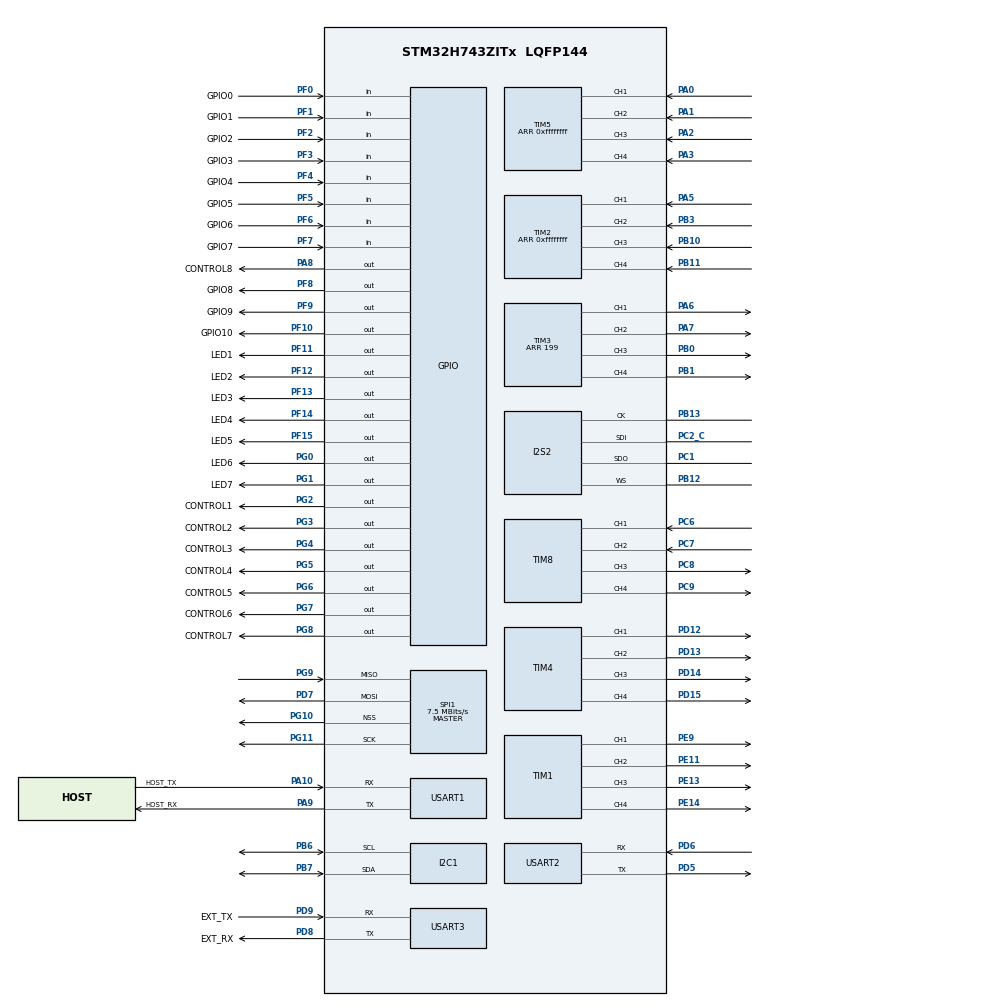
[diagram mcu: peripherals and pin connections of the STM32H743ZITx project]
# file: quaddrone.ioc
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Dma.Request0=TIM3_UP
Dma.Request1=TIM2_CH1
Dma.Request2=TIM2_CH2
Dma.Request3=TIM2_CH3
Dma.Request4=TIM2_CH4
Dma.Request5=TIM5_CH1
Dma.Request6=TIM5_CH2
Dma.Request7=TIM5_CH3
Dma.Request8=TIM5_CH4
Dma.TIM2_CH1.1.Direction=DMA_PERIPH_TO_MEMORY
Dma.TIM2_CH1.1.EventEnable=DISABLE
Dma.TIM2_CH1.1.FIFOMode=DMA_FIFOMODE_DISABLE
Dma.TIM2_CH1.1.Instance=DMA1_Stream1
Dma.TIM2_CH1.1.MemDataAlignment=DMA_MDATAALIGN_WORD
Dma.TIM2_CH1.1.MemInc=DMA_MINC_ENABLE
Dma.TIM2_CH1.1.Mode=DMA_NORMAL
Dma.TIM2_CH1.1.PeriphDataAlignment=DMA_PDATAALIGN_WORD
Dma.TIM2_CH1.1.PeriphInc=DMA_PINC_DISABLE
Dma.TIM2_CH1.1.Polarity=HAL_DMAMUX_REQ_GEN_RISING
Dma.TIM2_CH1.1.Priority=DMA_PRIORITY_LOW
Dma.TIM2_CH1.1.RequestNumber=1
Dma.TIM2_CH1.1.SignalID=NONE
Dma.TIM2_CH1.1.SyncEnable=DISABLE
Dma.TIM2_CH1.1.SyncPolarity=HAL_DMAMUX_SYNC_NO_EVENT
Dma.TIM2_CH1.1.SyncRequestNumber=1
Dma.TIM2_CH1.1.SyncSignalID=NONE
Dma.TIM2_CH2.2.Direction=DMA_PERIPH_TO_MEMORY
Dma.TIM2_CH2.2.EventEnable=DISABLE
Dma.TIM2_CH2.2.FIFOMode=DMA_FIFOMODE_DISABLE
Dma.TIM2_CH2.2.Instance=DMA1_Stream2
Dma.TIM2_CH2.2.MemDataAlignment=DMA_MDATAALIGN_WORD
Dma.TIM2_CH2.2.MemInc=DMA_MINC_ENABLE
Dma.TIM2_CH2.2.Mode=DMA_NORMAL
Dma.TIM2_CH2.2.PeriphDataAlignment=DMA_PDATAALIGN_WORD
Dma.TIM2_CH2.2.PeriphInc=DMA_PINC_DISABLE
Dma.TIM2_CH2.2.Polarity=HAL_DMAMUX_REQ_GEN_RISING
Dma.TIM2_CH2.2.Priority=DMA_PRIORITY_LOW
Dma.TIM2_CH2.2.RequestNumber=1
Dma.TIM2_CH2.2.SignalID=NONE
Dma.TIM2_CH2.2.SyncEnable=DISABLE
Dma.TIM2_CH2.2.SyncPolarity=HAL_DMAMUX_SYNC_NO_EVENT
Dma.TIM2_CH2.2.SyncRequestNumber=1
Dma.TIM2_CH2.2.SyncSignalID=NONE
Dma.TIM2_CH3.3.Direction=DMA_PERIPH_TO_MEMORY
Dma.TIM2_CH3.3.EventEnable=DISABLE
Dma.TIM2_CH3.3.FIFOMode=DMA_FIFOMODE_DISABLE
Dma.TIM2_CH3.3.Instance=DMA1_Stream3
Dma.TIM2_CH3.3.MemDataAlignment=DMA_MDATAALIGN_WORD
Dma.TIM2_CH3.3.MemInc=DMA_MINC_ENABLE
Dma.TIM2_CH3.3.Mode=DMA_NORMAL
Dma.TIM2_CH3.3.PeriphDataAlignment=DMA_PDATAALIGN_WORD
Dma.TIM2_CH3.3.PeriphInc=DMA_PINC_DISABLE
Dma.TIM2_CH3.3.Polarity=HAL_DMAMUX_REQ_GEN_RISING
Dma.TIM2_CH3.3.Priority=DMA_PRIORITY_LOW
Dma.TIM2_CH3.3.RequestNumber=1
Dma.TIM2_CH3.3.SignalID=NONE
Dma.TIM2_CH3.3.SyncEnable=DISABLE
Dma.TIM2_CH3.3.SyncPolarity=HAL_DMAMUX_SYNC_NO_EVENT
Dma.TIM2_CH3.3.SyncRequestNumber=1
Dma.TIM2_CH3.3.SyncSignalID=NONE
Dma.TIM2_CH4.4.Direction=DMA_PERIPH_TO_MEMORY
Dma.TIM2_CH4.4.EventEnable=DISABLE
Dma.TIM2_CH4.4.FIFOMode=DMA_FIFOMODE_DISABLE
Dma.TIM2_CH4.4.Instance=DMA1_Stream4
Dma.TIM2_CH4.4.MemDataAlignment=DMA_MDATAALIGN_WORD
Dma.TIM2_CH4.4.MemInc=DMA_MINC_ENABLE
Dma.TIM2_CH4.4.Mode=DMA_NORMAL
Dma.TIM2_CH4.4.PeriphDataAlignment=DMA_PDATAALIGN_WORD
Dma.TIM2_CH4.4.PeriphInc=DMA_PINC_DISABLE
Dma.TIM2_CH4.4.Polarity=HAL_DMAMUX_REQ_GEN_RISING
Dma.TIM2_CH4.4.Priority=DMA_PRIORITY_LOW
Dma.TIM2_CH4.4.RequestNumber=1
Dma.TIM2_CH4.4.SignalID=NONE
Dma.TIM2_CH4.4.SyncEnable=DISABLE
Dma.TIM2_CH4.4.SyncPolarity=HAL_DMAMUX_SYNC_NO_EVENT
Dma.TIM2_CH4.4.SyncRequestNumber=1
Dma.TIM2_CH4.4.SyncSignalID=NONE
Dma.TIM3_UP.0.Direction=DMA_MEMORY_TO_PERIPH
Dma.TIM3_UP.0.EventEnable=DISABLE
Dma.TIM3_UP.0.FIFOMode=DMA_FIFOMODE_DISABLE
Dma.TIM3_UP.0.Instance=DMA1_Stream0
Dma.TIM3_UP.0.MemDataAlignment=DMA_MDATAALIGN_WORD
Dma.TIM3_UP.0.MemInc=DMA_MINC_ENABLE
Dma.TIM3_UP.0.Mode=DMA_NORMAL
Dma.TIM3_UP.0.PeriphDataAlignment=DMA_PDATAALIGN_WORD
Dma.TIM3_UP.0.PeriphInc=DMA_PINC_DISABLE
Dma.TIM3_UP.0.Polarity=HAL_DMAMUX_REQ_GEN_RISING
Dma.TIM3_UP.0.Priority=DMA_PRIORITY_LOW
Dma.TIM3_UP.0.RequestNumber=1
Dma.TIM3_UP.0.SignalID=NONE
Dma.TIM3_UP.0.SyncEnable=DISABLE
Dma.TIM3_UP.0.SyncPolarity=HAL_DMAMUX_SYNC_NO_EVENT
Dma.TIM3_UP.0.SyncRequestNumber=1
Dma.TIM3_UP.0.SyncSignalID=NONE
Dma.TIM5_CH1.5.Direction=DMA_PERIPH_TO_MEMORY
Dma.TIM5_CH1.5.EventEnable=DISABLE
Dma.TIM5_CH1.5.FIFOMode=DMA_FIFOMODE_DISABLE
Dma.TIM5_CH1.5.Instance=DMA1_Stream5
Dma.TIM5_CH1.5.MemDataAlignment=DMA_MDATAALIGN_WORD
Dma.TIM5_CH1.5.MemInc=DMA_MINC_ENABLE
Dma.TIM5_CH1.5.Mode=DMA_NORMAL
Dma.TIM5_CH1.5.PeriphDataAlignment=DMA_PDATAALIGN_WORD
Dma.TIM5_CH1.5.PeriphInc=DMA_PINC_DISABLE
Dma.TIM5_CH1.5.Polarity=HAL_DMAMUX_REQ_GEN_RISING
Dma.TIM5_CH1.5.Priority=DMA_PRIORITY_LOW
Dma.TIM5_CH1.5.RequestNumber=1
Dma.TIM5_CH1.5.SignalID=NONE
Dma.TIM5_CH1.5.SyncEnable=DISABLE
Dma.TIM5_CH1.5.SyncPolarity=HAL_DMAMUX_SYNC_NO_EVENT
Dma.TIM5_CH1.5.SyncRequestNumber=1
Dma.TIM5_CH1.5.SyncSignalID=NONE
Dma.TIM5_CH2.6.Direction=DMA_PERIPH_TO_MEMORY
Dma.TIM5_CH2.6.EventEnable=DISABLE
Dma.TIM5_CH2.6.FIFOMode=DMA_FIFOMODE_DISABLE
Dma.TIM5_CH2.6.Instance=DMA1_Stream6
Dma.TIM5_CH2.6.MemDataAlignment=DMA_MDATAALIGN_WORD
Dma.TIM5_CH2.6.MemInc=DMA_MINC_ENABLE
Dma.TIM5_CH2.6.Mode=DMA_NORMAL
Dma.TIM5_CH2.6.PeriphDataAlignment=DMA_PDATAALIGN_WORD
Dma.TIM5_CH2.6.PeriphInc=DMA_PINC_DISABLE
Dma.TIM5_CH2.6.Polarity=HAL_DMAMUX_REQ_GEN_RISING
Dma.TIM5_CH2.6.Priority=DMA_PRIORITY_LOW
Dma.TIM5_CH2.6.RequestNumber=1
Dma.TIM5_CH2.6.SignalID=NONE
Dma.TIM5_CH2.6.SyncEnable=DISABLE
Dma.TIM5_CH2.6.SyncPolarity=HAL_DMAMUX_SYNC_NO_EVENT
Dma.TIM5_CH2.6.SyncRequestNumber=1
Dma.TIM5_CH2.6.SyncSignalID=NONE
Dma.TIM5_CH3.7.Direction=DMA_PERIPH_TO_MEMORY
Dma.TIM5_CH3.7.EventEnable=DISABLE
Dma.TIM5_CH3.7.FIFOMode=DMA_FIFOMODE_DISABLE
Dma.TIM5_CH3.7.Instance=DMA1_Stream7
Dma.TIM5_CH3.7.MemDataAlignment=DMA_MDATAALIGN_WORD
Dma.TIM5_CH3.7.MemInc=DMA_MINC_ENABLE
Dma.TIM5_CH3.7.Mode=DMA_NORMAL
Dma.TIM5_CH3.7.PeriphDataAlignment=DMA_PDATAALIGN_WORD
Dma.TIM5_CH3.7.PeriphInc=DMA_PINC_DISABLE
Dma.TIM5_CH3.7.Polarity=HAL_DMAMUX_REQ_GEN_RISING
Dma.TIM5_CH3.7.Priority=DMA_PRIORITY_LOW
Dma.TIM5_CH3.7.RequestNumber=1
Dma.TIM5_CH3.7.SignalID=NONE
Dma.TIM5_CH3.7.SyncEnable=DISABLE
Dma.TIM5_CH3.7.SyncPolarity=HAL_DMAMUX_SYNC_NO_EVENT
Dma.TIM5_CH3.7.SyncRequestNumber=1
Dma.TIM5_CH3.7.SyncSignalID=NONE
Dma.TIM5_CH4.8.Direction=DMA_PERIPH_TO_MEMORY
Dma.TIM5_CH4.8.EventEnable=DISABLE
Dma.TIM5_CH4.8.FIFOMode=DMA_FIFOMODE_DISABLE
Dma.TIM5_CH4.8.Instance=DMA2_Stream0
Dma.TIM5_CH4.8.MemDataAlignment=DMA_MDATAALIGN_WORD
Dma.TIM5_CH4.8.MemInc=DMA_MINC_ENABLE
Dma.TIM5_CH4.8.Mode=DMA_NORMAL
Dma.TIM5_CH4.8.PeriphDataAlignment=DMA_PDATAALIGN_WORD
Dma.TIM5_CH4.8.PeriphInc=DMA_PINC_DISABLE
Dma.TIM5_CH4.8.Polarity=HAL_DMAMUX_REQ_GEN_RISING
Dma.TIM5_CH4.8.Priority=DMA_PRIORITY_LOW
Dma.TIM5_CH4.8.RequestNumber=1
Dma.TIM5_CH4.8.SignalID=NONE
Dma.TIM5_CH4.8.SyncEnable=DISABLE
Dma.TIM5_CH4.8.SyncPolarity=HAL_DMAMUX_SYNC_NO_EVENT
Dma.TIM5_CH4.8.SyncRequestNumber=1
Dma.TIM5_CH4.8.SyncSignalID=NONE
I2C1.Timing=0x307075B1
I2S2.AudioFreq=I2S_AUDIOFREQ_32K
I2S2.DataFormat=I2S_DATAFORMAT_16B_EXTENDED
I2S2.ErrorAudioFreq=0.15 %
I2S2.FullDuplexMode=I2S_MODE_MASTER_FD
I2S2.Instance=SPI$Index
I2S2.RealAudioFreq=32.051 KHz
I2S2.VirtualMode=I2S_MODE_MASTER
Mcu.Family=STM32H7
Mcu.Name=STM32H743ZITx
Mcu.Package=LQFP144
NVIC.DMA1_Stream0_IRQn=true\:0\:0\:false\:false\:true\:false\:true
NVIC.DMA1_Stream1_IRQn=true\:0\:0\:false\:false\:true\:false\:true
NVIC.DMA1_Stream2_IRQn=true\:0\:0\:false\:false\:true\:false\:true
NVIC.DMA1_Stream3_IRQn=true\:0\:0\:false\:false\:true\:false\:true
NVIC.DMA1_Stream4_IRQn=true\:0\:0\:false\:false\:true\:false\:true
NVIC.DMA1_Stream5_IRQn=true\:0\:0\:false\:false\:true\:false\:true
NVIC.DMA1_Stream6_IRQn=true\:0\:0\:false\:false\:true\:false\:true
NVIC.DMA1_Stream7_IRQn=true\:0\:0\:false\:false\:true\:false\:true
NVIC.DMA2_Stream0_IRQn=true\:0\:0\:false\:false\:true\:false\:true
NVIC.PriorityGroup=NVIC_PRIORITYGROUP_4
NVIC.TIM1_BRK_IRQn=true\:0\:0\:false\:false\:true\:true\:true
NVIC.TIM1_CC_IRQn=true\:0\:0\:false\:false\:true\:true\:true
NVIC.TIM1_TRG_COM_IRQn=true\:0\:0\:false\:false\:true\:true\:true
NVIC.TIM1_UP_IRQn=true\:0\:0\:false\:false\:true\:true\:true
NVIC.TIM2_IRQn=true\:0\:0\:false\:false\:true\:true\:true
NVIC.TIM3_IRQn=true\:0\:0\:false\:false\:true\:true\:true
NVIC.TIM5_IRQn=true\:0\:0\:false\:false\:true\:true\:true
NVIC.USART1_IRQn=true\:0\:0\:false\:false\:true\:true\:true
NVIC.USART2_IRQn=true\:0\:0\:false\:false\:true\:true\:true
NVIC.USART3_IRQn=true\:0\:0\:false\:false\:true\:true\:true
PA0.Signal=S_TIM5_CH1
PA1.Signal=S_TIM5_CH2
PA10.GPIO_Label=HOST_TX
PA10.Mode=Asynchronous
PA10.Signal=USART1_RX
PA2.Signal=S_TIM5_CH3
PA3.Signal=S_TIM5_CH4
PA5.Signal=S_TIM2_CH1
PA6.Signal=S_TIM3_CH1
PA7.Signal=S_TIM3_CH2
PA8.GPIO_Label=CONTROL8
PA8.Signal=GPIO_Output
PA9.GPIO_Label=HOST_RX
PA9.Mode=Asynchronous
PA9.Signal=USART1_TX
PB0.Signal=S_TIM3_CH3
PB1.Signal=S_TIM3_CH4
PB10.Signal=S_TIM2_CH3
PB11.Signal=S_TIM2_CH4
PB12.Mode=Full_Duplex_Master
PB12.Signal=I2S2_WS
PB13.Mode=Full_Duplex_Master
PB13.Signal=I2S2_CK
PB3\ (JTDO/TRACESWO).Signal=S_TIM2_CH2
PB6.Mode=I2C
PB6.Signal=I2C1_SCL
PB7.Mode=I2C
PB7.Signal=I2C1_SDA
PC1.Mode=Full_Duplex_Master
PC1.Signal=I2S2_SDO
PC2_C.Mode=Full_Duplex_Master
PC2_C.Signal=I2S2_SDI
PC6.Signal=S_TIM8_CH1
PC7.Signal=S_TIM8_CH2
PC8.Signal=S_TIM8_CH3
PC9.Signal=S_TIM8_CH4
PD12.Signal=S_TIM4_CH1
PD13.Signal=S_TIM4_CH2
PD14.Signal=S_TIM4_CH3
PD15.Signal=S_TIM4_CH4
PD5.Mode=Asynchronous
PD5.Signal=USART2_TX
PD6.Mode=Asynchronous
PD6.Signal=USART2_RX
PD7.Mode=Full_Duplex_Master
PD7.Signal=SPI1_MOSI
PD8.GPIO_Label=EXT_RX
PD8.Mode=Asynchronous
PD8.Signal=USART3_TX
PD9.GPIO_Label=EXT_TX
PD9.Mode=Asynchronous
PD9.Signal=USART3_RX
PE11.Signal=S_TIM1_CH2
PE13.Signal=S_TIM1_CH3
PE14.Signal=S_TIM1_CH4
PE9.Signal=S_TIM1_CH1
PF0.GPIO_Label=GPIO0
PF0.Signal=GPIO_Input
PF1.GPIO_Label=GPIO1
PF1.Signal=GPIO_Input
PF10.GPIO_Label=GPIO10
PF10.Signal=GPIO_Output
PF11.GPIO_Label=LED1
PF11.Signal=GPIO_Output
PF12.GPIO_Label=LED2
PF12.Signal=GPIO_Output
PF13.GPIO_Label=LED3
PF13.Signal=GPIO_Output
PF14.GPIO_Label=LED4
PF14.Signal=GPIO_Output
PF15.GPIO_Label=LED5
PF15.Signal=GPIO_Output
PF2.GPIO_Label=GPIO2
PF2.Signal=GPIO_Input
PF3.GPIO_Label=GPIO3
PF3.Signal=GPIO_Input
PF4.GPIO_Label=GPIO4
PF4.Signal=GPIO_Input
PF5.GPIO_Label=GPIO5
PF5.Signal=GPIO_Input
PF6.GPIO_Label=GPIO6
PF6.Signal=GPIO_Input
PF7.GPIO_Label=GPIO7
PF7.Signal=GPIO_Input
PF8.GPIO_Label=GPIO8
PF8.Signal=GPIO_Output
PF9.GPIO_Label=GPIO9
PF9.Signal=GPIO_Output
PG0.GPIO_Label=LED6
PG0.Signal=GPIO_Output
PG1.GPIO_Label=LED7
PG1.Signal=GPIO_Output
PG10.Mode=NSS_Signal_Hard_Output
PG10.Signal=SPI1_NSS
PG11.Mode=Full_Duplex_Master
PG11.Signal=SPI1_SCK
PG2.GPIO_Label=CONTROL1
PG2.Signal=GPIO_Output
PG3.GPIO_Label=CONTROL2
PG3.Signal=GPIO_Output
PG4.GPIO_Label=CONTROL3
PG4.Signal=GPIO_Output
PG5.GPIO_Label=CONTROL4
PG5.Signal=GPIO_Output
PG6.GPIO_Label=CONTROL5
PG6.Signal=GPIO_Output
PG7.GPIO_Label=CONTROL6
PG7.Signal=GPIO_Output
PG8.GPIO_Label=CONTROL7
PG8.Signal=GPIO_Output
PG9.Mode=Full_Duplex_Master
PG9.Signal=SPI1_MISO
PH0-OSC_IN\ (PH0).Mode=HSE-External-Oscillator
PH0-OSC_IN\ (PH0).Signal=RCC_OSC_IN
PH1-OSC_OUT\ (PH1).Mode=HSE-External-Oscillator
PH1-OSC_OUT\ (PH1).Signal=RCC_OSC_OUT
ProjectManager.HeapSize=0x200
ProjectManager.StackSize=0x400
ProjectManager.TargetToolchain=SW4STM32
RCC.ADCFreq_Value=288000000
RCC.APB1Freq_Value=120000000
RCC.APB2Freq_Value=120000000
RCC.APB3Freq_Value=120000000
RCC.APB4Freq_Value=120000000
RCC.CortexFreq_Value=480000000
RCC.D1PPRE=RCC_APB3_DIV2
RCC.D2PPRE1=RCC_APB1_DIV2
RCC.D2PPRE2=RCC_APB2_DIV2
RCC.D3PPRE=RCC_APB4_DIV2
RCC.DIVM1=2
RCC.DIVM2=2
RCC.DIVN1=120
RCC.DIVN2=72
RCC.HCLKFreq_Value=240000000
RCC.HPRE=RCC_HCLK_DIV2
RCC.HSE_VALUE=16000000
RCC.PLLSourceVirtual=RCC_PLLSOURCE_HSE
RCC.SYSCLKFreq_VALUE=480000000
RCC.SYSCLKSource=RCC_SYSCLKSOURCE_PLLCLK
RCC.USART234578CLockSelection=RCC_USART234578CLKSOURCE_PLL2
RCC.USBFreq_Value=480000000
SH.S_TIM1_CH1.0=TIM1_CH1,PWM Generation1 CH1
SH.S_TIM1_CH2.0=TIM1_CH2,PWM Generation2 CH2
SH.S_TIM1_CH3.0=TIM1_CH3,PWM Generation3 CH3
SH.S_TIM1_CH4.0=TIM1_CH4,PWM Generation4 CH4
SH.S_TIM2_CH1.0=TIM2_CH1,Input_Capture1_from_TI1
SH.S_TIM2_CH1.1=TIM2_CH1
SH.S_TIM2_CH2.0=TIM2_CH2,Input_Capture2_from_TI2
SH.S_TIM2_CH3.0=TIM2_CH3,Input_Capture3_from_TI3
SH.S_TIM2_CH3.1=TIM2_CH3
SH.S_TIM2_CH4.0=TIM2_CH4,Input_Capture4_from_TI4
SH.S_TIM3_CH1.0=TIM3_CH1,PWM Generation1 CH1
SH.S_TIM3_CH2.0=TIM3_CH2,PWM Generation2 CH2
SH.S_TIM3_CH3.0=TIM3_CH3,PWM Generation3 CH3
SH.S_TIM3_CH4.0=TIM3_CH4,PWM Generation4 CH4
SH.S_TIM4_CH1.0=TIM4_CH1,PWM Generation1 CH1
SH.S_TIM4_CH2.0=TIM4_CH2,PWM Generation2 CH2
SH.S_TIM4_CH3.0=TIM4_CH3,PWM Generation3 CH3
SH.S_TIM4_CH4.0=TIM4_CH4,PWM Generation4 CH4
SH.S_TIM5_CH1.0=TIM5_CH1,Input_Capture1_from_TI1
SH.S_TIM5_CH1.1=TIM5_CH1
SH.S_TIM5_CH2.0=TIM5_CH2,Input_Capture2_from_TI2
SH.S_TIM5_CH3.0=TIM5_CH3,Input_Capture3_from_TI3
SH.S_TIM5_CH3.1=TIM5_CH3
SH.S_TIM5_CH4.0=TIM5_CH4,Input_Capture4_from_TI4
SH.S_TIM8_CH1.0=TIM8_CH1,Input_Capture1_from_TI1
SH.S_TIM8_CH2.0=TIM8_CH2,Input_Capture2_from_TI2
SH.S_TIM8_CH3.0=TIM8_CH3,PWM Generation3 CH3
SH.S_TIM8_CH4.0=TIM8_CH4,PWM Generation4 CH4
SPI1.BaudRatePrescaler=SPI_BAUDRATEPRESCALER_64
SPI1.CalculateBaudRate=7.5 MBits/s
SPI1.Direction=SPI_DIRECTION_2LINES
SPI1.Mode=SPI_MODE_MASTER
SPI1.VirtualNSS=VM_NSSHARD
SPI1.VirtualType=VM_MASTER
TIM1.Channel-PWM\ Generation1\ CH1=TIM_CHANNEL_1
TIM1.Channel-PWM\ Generation2\ CH2=TIM_CHANNEL_2
TIM1.Channel-PWM\ Generation3\ CH3=TIM_CHANNEL_3
TIM1.Channel-PWM\ Generation4\ CH4=TIM_CHANNEL_4
TIM2.Channel-Input_Capture1_from_TI1=TIM_CHANNEL_1
TIM2.Channel-Input_Capture2_from_TI2=TIM_CHANNEL_2
TIM2.Channel-Input_Capture3_from_TI3=TIM_CHANNEL_3
TIM2.Channel-Input_Capture4_from_TI4=TIM_CHANNEL_4
TIM2.ICPolarity_CH1=TIM_INPUTCHANNELPOLARITY_BOTHEDGE
TIM2.ICPolarity_CH2=TIM_INPUTCHANNELPOLARITY_BOTHEDGE
TIM2.ICPolarity_CH3=TIM_INPUTCHANNELPOLARITY_BOTHEDGE
TIM2.ICPolarity_CH4=TIM_INPUTCHANNELPOLARITY_BOTHEDGE
TIM2.Period=0xffffffff
TIM2.TIM_MasterOutputTrigger=TIM_TRGO_OC1
TIM2.TIM_MasterSlaveMode=TIM_MASTERSLAVEMODE_ENABLE
TIM3.AutoReloadPreload=TIM_AUTORELOAD_PRELOAD_ENABLE
TIM3.Channel-PWM\ Generation1\ CH1=TIM_CHANNEL_1
TIM3.Channel-PWM\ Generation2\ CH2=TIM_CHANNEL_2
TIM3.Channel-PWM\ Generation3\ CH3=TIM_CHANNEL_3
TIM3.Channel-PWM\ Generation4\ CH4=TIM_CHANNEL_4
TIM3.Period=199
TIM4.Channel-PWM\ Generation1\ CH1=TIM_CHANNEL_1
TIM4.Channel-PWM\ Generation2\ CH2=TIM_CHANNEL_2
TIM4.Channel-PWM\ Generation3\ CH3=TIM_CHANNEL_3
TIM4.Channel-PWM\ Generation4\ CH4=TIM_CHANNEL_4
TIM5.Channel-Input_Capture1_from_TI1=TIM_CHANNEL_1
TIM5.Channel-Input_Capture2_from_TI2=TIM_CHANNEL_2
TIM5.Channel-Input_Capture3_from_TI3=TIM_CHANNEL_3
TIM5.Channel-Input_Capture4_from_TI4=TIM_CHANNEL_4
TIM5.ICPolarity_CH1=TIM_INPUTCHANNELPOLARITY_BOTHEDGE
TIM5.ICPolarity_CH2=TIM_INPUTCHANNELPOLARITY_BOTHEDGE
TIM5.ICPolarity_CH3=TIM_INPUTCHANNELPOLARITY_BOTHEDGE
TIM5.ICPolarity_CH4=TIM_INPUTCHANNELPOLARITY_BOTHEDGE
TIM5.Period=0xffffffff
TIM8.Channel-Input_Capture1_from_TI1=TIM_CHANNEL_1
TIM8.Channel-Input_Capture2_from_TI2=TIM_CHANNEL_2
TIM8.Channel-Output\ Compare6\ No\ Output=TIM_CHANNEL_6
TIM8.Channel-PWM\ Generation3\ CH3=TIM_CHANNEL_3
TIM8.Channel-PWM\ Generation4\ CH4=TIM_CHANNEL_4
TIM8.Channel-PWM\ Generation5\ No\ Output=TIM_CHANNEL_5
USART1.VirtualMode-Asynchronous=VM_ASYNC
USART2.VirtualMode-Asynchronous=VM_ASYNC
USART3.VirtualMode-Asynchronous=VM_ASYNC
VP_TIM1_VS_ClockSourceINT.Mode=Internal
VP_TIM1_VS_ClockSourceITR.Mode=TriggerSource_ITR1
VP_TIM1_VS_ControllerModeReset.Mode=Reset Mode
VP_TIM2_VS_ClockSourceINT.Mode=Internal
VP_TIM3_VS_ClockSourceINT.Mode=Internal
VP_TIM3_VS_ClockSourceITR.Mode=TriggerSource_ITR1
VP_TIM3_VS_ControllerModeReset.Mode=Reset Mode
VP_TIM4_VS_ClockSourceINT.Mode=Internal
VP_TIM5_VS_ClockSourceINT.Mode=Internal
VP_TIM8_VS_ClockSourceINT.Mode=Internal
VP_TIM8_VS_no_output5.Mode=PWM Generation5 No Output
VP_TIM8_VS_no_output6.Mode=Output Compare6 No Output
board=custom

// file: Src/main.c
/* USER CODE BEGIN Header */
/**
  ******************************************************************************
  * @file           : main.c
  * @brief          : Main program body
  ******************************************************************************
  * @attention
  *
  * <h2><center>&copy; Copyright (c) 2020 STMicroelectronics.
  * All rights reserved.</center></h2>
  *
  * This software component is licensed by ST under BSD 3-Clause license,
  * the "License"; You may not use this file except in compliance with the
  * License. You may obtain a copy of the License at:
  *                        opensource.org/licenses/BSD-3-Clause
  *
  ******************************************************************************
  */
/* USER CODE END Header */

#include "main.h"

I2C_HandleTypeDef hi2c1;

I2S_HandleTypeDef hi2s2;

SPI_HandleTypeDef hspi1;

TIM_HandleTypeDef htim1;
TIM_HandleTypeDef htim2;
TIM_HandleTypeDef htim3;
TIM_HandleTypeDef htim4;
TIM_HandleTypeDef htim5;
TIM_HandleTypeDef htim8;
DMA_HandleTypeDef hdma_tim2_ch1;
DMA_HandleTypeDef hdma_tim2_ch2;
DMA_HandleTypeDef hdma_tim2_ch3;
DMA_HandleTypeDef hdma_tim2_ch4;
DMA_HandleTypeDef hdma_tim3_up;
DMA_HandleTypeDef hdma_tim5_ch1;
DMA_HandleTypeDef hdma_tim5_ch2;
DMA_HandleTypeDef hdma_tim5_ch3;
DMA_HandleTypeDef hdma_tim5_ch4;

UART_HandleTypeDef huart1;
UART_HandleTypeDef huart2;
UART_HandleTypeDef huart3;

void SystemClock_Config(void);
static void MX_GPIO_Init(void);
static void MX_DMA_Init(void);
static void MX_I2C1_Init(void);
static void MX_SPI1_Init(void);
static void MX_TIM1_Init(void);
static void MX_TIM2_Init(void);
static void MX_TIM3_Init(void);
static void MX_TIM4_Init(void);
static void MX_TIM5_Init(void);
static void MX_TIM8_Init(void);
static void MX_USART1_UART_Init(void);
static void MX_USART3_UART_Init(void);
static void MX_I2S2_Init(void);
static void MX_USART2_UART_Init(void);
/* USER CODE BEGIN PFP */

/* four channels, 16 bits per packet */
#define DShotChannels (4)
#define DShotWordLength (16)
#define DShotPacketLength (DShotWordLength + 1)
uint32_t dshot_ccr_buffer[DShotPacketLength][DShotChannels] __attribute__ ((aligned(4), section(".dma_buffer")));
uint32_t dshot_incoming_buffer[DShotChannels][2 * DShotWordLength] __attribute__ ((aligned(4), section(".dma_buffer")));
static const uint32_t DShotPeriod = 199; /* 200 - 1 */
static const uint32_t DShotHi = 149; /* 75% of 200 - 1 */
static const uint32_t DShotLo = 74; /* 50% of 75% of 200 - 1 */

/* USER CODE END PFP */

/* USER CODE BEGIN 0 */

void init_dshot()
{
	for (int i = 0; i < DShotChannels; ++i) {
		for (int j = 0; j < DShotPacketLength; ++j) {
			dshot_ccr_buffer[j][i] = 0;
		}
	}

	for (int i = 0; i < DShotChannels; ++i) {
		for (int j = 0; j < DShotWordLength; ++j) {
			dshot_incoming_buffer[i][j] = 0;
		}
	}
}

void send_channel_dshot(unsigned int channel, uint16_t pwm, unsigned int send_flag)
{
	uint32_t *p = &dshot_ccr_buffer[0][channel];
	for (int i = 15; i >= 0; --i) {
		*p = ((pwm >> i) & 1) ? DShotHi : DShotLo;
		p += DShotChannels;
	}

	*p = 0;
	p += DShotChannels;

	if (send_flag) {
		DMA_HandleTypeDef *hdma = htim3.hdma[0];
		DMA_Stream_TypeDef *dma_stream = hdma->Instance;
		dma_stream->NDTR = DShotPacketLength * DShotChannels;
		dma_stream->CR |= (DMA_SxCR_TCIE);
		dma_stream->CR |= (DMA_SxCR_EN);

		TIM_TypeDef *tim = &htim3.Instance;
		tim->EGR = TIM_EGR_UG;
	}
}

void load_dshot(uint16_t pwm[4])
{
	for (int channel = 0; channel < DShotChannels; ++channel) {
		uint32_t *p = &dshot_ccr_buffer[0][channel];
		uint16_t pulse_duration = pwm[channel];
		for (int i = 15; i >= 0; --i) {
			*p = ((pulse_duration >> i) & 1) ? DShotHi : DShotLo;
			p += DShotChannels;
		}
		*p = 0;
	}
}

void fire_dshot(void)
{
	TIM_HandleTypeDef *htim = &htim3;
	TIM_TypeDef *tim = htim->Instance;
	DMA_HandleTypeDef *hdma = htim->hdma[0];
	DMA_Stream_TypeDef *dma_stream = hdma->Instance;

	dma_stream->CR &= ~(DMA_SxCR_EN);
	dma_stream->NDTR = DShotPacketLength * DShotChannels;
	dma_stream->CR |= (DMA_SxCR_TCIE);
	dma_stream->M0AR = dshot_ccr_buffer;
	dma_stream->PAR = &tim->DMAR;
	dma_stream->CR |= (DMA_SxCR_EN);

	// tim->EGR = TIM_EGR_UG;
}

void send_dshot(uint16_t pwm[4], unsigned int send_flag)
{
	load_dshot(pwm);
	if (send_flag) { fire_dshot(); }
}

void recv_dshot()
{
	TIM_HandleTypeDef *htim = &htim5;
	TIM_TypeDef *tim = htim->Instance;
	DMA_HandleTypeDef *hdma;
	DMA_Stream_TypeDef *dma_stream;
	const int TimChan1DmaIndex = 1;
	const int TimChan2DmaIndex = 2;
	const int TimChan3DmaIndex = 3;
	const int TimChan4DmaIndex = 4;

	const uint32_t xfer_size = 2 * DShotWordLength;

	hdma = htim->hdma[TimChan1DmaIndex];
	dma_stream = hdma->Instance;
	dma_stream->CR &= ~(DMA_SxCR_EN);
	dma_stream->NDTR = xfer_size;
	dma_stream->CR |= (DMA_SxCR_TCIE);
	dma_stream->M0AR = dshot_incoming_buffer[0];
	dma_stream->PAR = &tim->CCR1;
	dma_stream->CR |= (DMA_SxCR_EN);

	hdma = htim->hdma[TimChan2DmaIndex];
	dma_stream = hdma->Instance;
	dma_stream->CR &= ~(DMA_SxCR_EN);
	dma_stream->NDTR = xfer_size;
	dma_stream->CR |= (DMA_SxCR_TCIE);
	dma_stream->M0AR = dshot_incoming_buffer[1];
	dma_stream->PAR = &tim->CCR2;
	dma_stream->CR |= (DMA_SxCR_EN);

	hdma = htim->hdma[TimChan3DmaIndex];
	dma_stream = hdma->Instance;
	dma_stream->CR &= ~(DMA_SxCR_EN);
	dma_stream->NDTR = xfer_size;
	dma_stream->CR |= (DMA_SxCR_TCIE);
	dma_stream->M0AR = dshot_incoming_buffer[2];
	dma_stream->PAR = &tim->CCR3;
	dma_stream->CR |= (DMA_SxCR_EN);

	hdma = htim->hdma[TimChan4DmaIndex];
	dma_stream = hdma->Instance;
	dma_stream->CR &= ~(DMA_SxCR_EN);
	dma_stream->NDTR = xfer_size;
	dma_stream->CR |= (DMA_SxCR_TCIE);
	dma_stream->M0AR = dshot_incoming_buffer[3];
	dma_stream->PAR = &tim->CCR4;
	dma_stream->CR |= (DMA_SxCR_EN);

}

int analyze_shot(int channel, uint16_t *result)
{
	uint32_t acc1 = 0, acc2 = 0, acc0 = DShotWordLength - 1;
	uint16_t bit_length[16];
	uint32_t *p = dshot_incoming_buffer[channel];
	uint32_t delta;
	for (int i = 0; i < acc0; ++i) {
		uint32_t t0 = p[2*i];
		delta = p[2*i+1] - t0;
		bit_length[i] = delta;
		delta = p[2*i+2] - t0;
		acc1 += delta;
		acc2 += (delta * delta);
	}
	uint32_t mean = acc1 / acc0;
	uint32_t var2 = acc2 / acc0;
	uint32_t var2_max = 100 + mean * mean;
	uint32_t tolerance = mean / 20; /* 5% tolerance */
	uint32_t thresh1 = 3 * mean / 4 - tolerance;
	uint32_t thresh0 = thresh1 / 2 + tolerance;
	uint16_t dshot = 0;
	int errors = 0;
	if (var2 <= var2_max) { /* calculated mean is a good central value */
		for (int i = 0; i < DShotWordLength; ++i) {
			dshot = (dshot << 1);
			if (bit_length[i] > thresh1) {
				dshot = dshot | 1;
			} else if (bit_length[i] < thresh0) {
			} else {
				++errors;
			}
		}
	}
	*result = dshot;
	return errors;
}

/* USER CODE END 0 */

int main(void)
{

  /* MCU Configuration--------------------------------------------------------*/

  /* Reset of all peripherals, Initializes the Flash interface and the Systick. */
  HAL_Init();

  /* Configure the system clock */
  SystemClock_Config();

  /* Initialize all configured peripherals */
  MX_GPIO_Init();
  MX_DMA_Init();
  MX_I2C1_Init();
  MX_SPI1_Init();
  MX_TIM1_Init();
  MX_TIM2_Init();
  MX_TIM3_Init();
  MX_TIM4_Init();
  MX_TIM5_Init();
  MX_TIM8_Init();
  MX_USART1_UART_Init();
  MX_USART3_UART_Init();
  MX_I2S2_Init();
  MX_USART2_UART_Init();
  /* USER CODE BEGIN 2 */

  init_dshot();

  uint16_t pwm[4];
  pwm[0] = 0xaaaa;
  pwm[1] = 0x5555;
  pwm[2] = 0xcccc;
  pwm[3] = 0x3333;
  load_dshot(pwm);

  /* USER CODE END 2 */

  /* Infinite loop */
  /* USER CODE BEGIN WHILE */
  uint16_t dshot;
  int rc, channel = 0;
  while (1)
  {
	  recv_dshot();
	  fire_dshot();
	  HAL_Delay(100);
	  rc = analyze_shot(channel, &dshot);

    /* USER CODE END WHILE */

  }
}

void SystemClock_Config(void)
{
  RCC_OscInitTypeDef RCC_OscInitStruct = {0};
  RCC_ClkInitTypeDef RCC_ClkInitStruct = {0};
  RCC_PeriphCLKInitTypeDef PeriphClkInitStruct = {0};

  /** Supply configuration update enable
  */
  HAL_PWREx_ConfigSupply(PWR_LDO_SUPPLY);
  /** Configure the main internal regulator output voltage
  */
  __HAL_PWR_VOLTAGESCALING_CONFIG(PWR_REGULATOR_VOLTAGE_SCALE0);

  while(!__HAL_PWR_GET_FLAG(PWR_FLAG_VOSRDY)) {}
  /** Macro to configure the PLL clock source
  */
  __HAL_RCC_PLL_PLLSOURCE_CONFIG(RCC_PLLSOURCE_HSE);
  /** Initializes the CPU, AHB and APB busses clocks
  */
  RCC_OscInitStruct.OscillatorType = RCC_OSCILLATORTYPE_HSE;
  RCC_OscInitStruct.HSEState = RCC_HSE_ON;
  RCC_OscInitStruct.PLL.PLLState = RCC_PLL_ON;
  RCC_OscInitStruct.PLL.PLLSource = RCC_PLLSOURCE_HSE;
  RCC_OscInitStruct.PLL.PLLM = 2;
  RCC_OscInitStruct.PLL.PLLN = 120;
  RCC_OscInitStruct.PLL.PLLP = 2;
  RCC_OscInitStruct.PLL.PLLQ = 2;
  RCC_OscInitStruct.PLL.PLLR = 2;
  RCC_OscInitStruct.PLL.PLLRGE = RCC_PLL1VCIRANGE_3;
  RCC_OscInitStruct.PLL.PLLVCOSEL = RCC_PLL1VCOWIDE;
  RCC_OscInitStruct.PLL.PLLFRACN = 0;
  if (HAL_RCC_OscConfig(&RCC_OscInitStruct) != HAL_OK)
  {
    Error_Handler();
  }
  /** Initializes the CPU, AHB and APB busses clocks
  */
  RCC_ClkInitStruct.ClockType = RCC_CLOCKTYPE_HCLK|RCC_CLOCKTYPE_SYSCLK
                              |RCC_CLOCKTYPE_PCLK1|RCC_CLOCKTYPE_PCLK2
                              |RCC_CLOCKTYPE_D3PCLK1|RCC_CLOCKTYPE_D1PCLK1;
  RCC_ClkInitStruct.SYSCLKSource = RCC_SYSCLKSOURCE_PLLCLK;
  RCC_ClkInitStruct.SYSCLKDivider = RCC_SYSCLK_DIV1;
  RCC_ClkInitStruct.AHBCLKDivider = RCC_HCLK_DIV2;
  RCC_ClkInitStruct.APB3CLKDivider = RCC_APB3_DIV2;
  RCC_ClkInitStruct.APB1CLKDivider = RCC_APB1_DIV2;
  RCC_ClkInitStruct.APB2CLKDivider = RCC_APB2_DIV2;
  RCC_ClkInitStruct.APB4CLKDivider = RCC_APB4_DIV2;

  if (HAL_RCC_ClockConfig(&RCC_ClkInitStruct, FLASH_LATENCY_4) != HAL_OK)
  {
    Error_Handler();
  }
  PeriphClkInitStruct.PeriphClockSelection = RCC_PERIPHCLK_USART3|RCC_PERIPHCLK_USART2
                              |RCC_PERIPHCLK_USART1|RCC_PERIPHCLK_SPI1
                              |RCC_PERIPHCLK_SPI2|RCC_PERIPHCLK_I2C1;
  PeriphClkInitStruct.PLL2.PLL2M = 2;
  PeriphClkInitStruct.PLL2.PLL2N = 72;
  PeriphClkInitStruct.PLL2.PLL2P = 2;
  PeriphClkInitStruct.PLL2.PLL2Q = 2;
  PeriphClkInitStruct.PLL2.PLL2R = 2;
  PeriphClkInitStruct.PLL2.PLL2RGE = RCC_PLL2VCIRANGE_3;
  PeriphClkInitStruct.PLL2.PLL2VCOSEL = RCC_PLL2VCOWIDE;
  PeriphClkInitStruct.PLL2.PLL2FRACN = 0;
  PeriphClkInitStruct.Spi123ClockSelection = RCC_SPI123CLKSOURCE_PLL;
  PeriphClkInitStruct.Usart234578ClockSelection = RCC_USART234578CLKSOURCE_PLL2;
  PeriphClkInitStruct.Usart16ClockSelection = RCC_USART16CLKSOURCE_D2PCLK2;
  PeriphClkInitStruct.I2c123ClockSelection = RCC_I2C123CLKSOURCE_D2PCLK1;
  if (HAL_RCCEx_PeriphCLKConfig(&PeriphClkInitStruct) != HAL_OK)
  {
    Error_Handler();
  }
}

static void MX_I2C1_Init(void)
{

  hi2c1.Instance = I2C1;
  hi2c1.Init.Timing = 0x307075B1;
  hi2c1.Init.OwnAddress1 = 0;
  hi2c1.Init.AddressingMode = I2C_ADDRESSINGMODE_7BIT;
  hi2c1.Init.DualAddressMode = I2C_DUALADDRESS_DISABLE;
  hi2c1.Init.OwnAddress2 = 0;
  hi2c1.Init.OwnAddress2Masks = I2C_OA2_NOMASK;
  hi2c1.Init.GeneralCallMode = I2C_GENERALCALL_DISABLE;
  hi2c1.Init.NoStretchMode = I2C_NOSTRETCH_DISABLE;
  if (HAL_I2C_Init(&hi2c1) != HAL_OK)
  {
    Error_Handler();
  }
  /** Configure Analogue filter
  */
  if (HAL_I2CEx_ConfigAnalogFilter(&hi2c1, I2C_ANALOGFILTER_ENABLE) != HAL_OK)
  {
    Error_Handler();
  }
  /** Configure Digital filter
  */
  if (HAL_I2CEx_ConfigDigitalFilter(&hi2c1, 0) != HAL_OK)
  {
    Error_Handler();
  }

}

static void MX_I2S2_Init(void)
{

  hi2s2.Instance = SPI2;
  hi2s2.Init.Mode = I2S_MODE_MASTER_TX;
  hi2s2.Init.Standard = I2S_STANDARD_PHILIPS;
  hi2s2.Init.DataFormat = I2S_DATAFORMAT_16B_EXTENDED;
  hi2s2.Init.MCLKOutput = I2S_MCLKOUTPUT_DISABLE;
  hi2s2.Init.AudioFreq = I2S_AUDIOFREQ_32K;
  hi2s2.Init.CPOL = I2S_CPOL_LOW;
  hi2s2.Init.FirstBit = I2S_FIRSTBIT_MSB;
  hi2s2.Init.WSInversion = I2S_WS_INVERSION_DISABLE;
  hi2s2.Init.Data24BitAlignment = I2S_DATA_24BIT_ALIGNMENT_RIGHT;
  hi2s2.Init.MasterKeepIOState = I2S_MASTER_KEEP_IO_STATE_DISABLE;
  if (HAL_I2S_Init(&hi2s2) != HAL_OK)
  {
    Error_Handler();
  }

}

static void MX_SPI1_Init(void)
{

  /* SPI1 parameter configuration*/
  hspi1.Instance = SPI1;
  hspi1.Init.Mode = SPI_MODE_MASTER;
  hspi1.Init.Direction = SPI_DIRECTION_2LINES;
  hspi1.Init.DataSize = SPI_DATASIZE_4BIT;
  hspi1.Init.CLKPolarity = SPI_POLARITY_LOW;
  hspi1.Init.CLKPhase = SPI_PHASE_1EDGE;
  hspi1.Init.NSS = SPI_NSS_HARD_OUTPUT;
  hspi1.Init.BaudRatePrescaler = SPI_BAUDRATEPRESCALER_64;
  hspi1.Init.FirstBit = SPI_FIRSTBIT_MSB;
  hspi1.Init.TIMode = SPI_TIMODE_DISABLE;
  hspi1.Init.CRCCalculation = SPI_CRCCALCULATION_DISABLE;
  hspi1.Init.CRCPolynomial = 0x0;
  hspi1.Init.NSSPMode = SPI_NSS_PULSE_ENABLE;
  hspi1.Init.NSSPolarity = SPI_NSS_POLARITY_LOW;
  hspi1.Init.FifoThreshold = SPI_FIFO_THRESHOLD_01DATA;
  hspi1.Init.TxCRCInitializationPattern = SPI_CRC_INITIALIZATION_ALL_ZERO_PATTERN;
  hspi1.Init.RxCRCInitializationPattern = SPI_CRC_INITIALIZATION_ALL_ZERO_PATTERN;
  hspi1.Init.MasterSSIdleness = SPI_MASTER_SS_IDLENESS_00CYCLE;
  hspi1.Init.MasterInterDataIdleness = SPI_MASTER_INTERDATA_IDLENESS_00CYCLE;
  hspi1.Init.MasterReceiverAutoSusp = SPI_MASTER_RX_AUTOSUSP_DISABLE;
  hspi1.Init.MasterKeepIOState = SPI_MASTER_KEEP_IO_STATE_DISABLE;
  hspi1.Init.IOSwap = SPI_IO_SWAP_DISABLE;
  if (HAL_SPI_Init(&hspi1) != HAL_OK)
  {
    Error_Handler();
  }

}

static void MX_TIM1_Init(void)
{

  TIM_ClockConfigTypeDef sClockSourceConfig = {0};
  TIM_SlaveConfigTypeDef sSlaveConfig = {0};
  TIM_MasterConfigTypeDef sMasterConfig = {0};
  TIM_OC_InitTypeDef sConfigOC = {0};
  TIM_BreakDeadTimeConfigTypeDef sBreakDeadTimeConfig = {0};

  htim1.Instance = TIM1;
  htim1.Init.Prescaler = 0;
  htim1.Init.CounterMode = TIM_COUNTERMODE_UP;
  htim1.Init.Period = 0;
  htim1.Init.ClockDivision = TIM_CLOCKDIVISION_DIV1;
  htim1.Init.RepetitionCounter = 0;
  htim1.Init.AutoReloadPreload = TIM_AUTORELOAD_PRELOAD_DISABLE;
  if (HAL_TIM_Base_Init(&htim1) != HAL_OK)
  {
    Error_Handler();
  }
  sClockSourceConfig.ClockSource = TIM_CLOCKSOURCE_INTERNAL;
  if (HAL_TIM_ConfigClockSource(&htim1, &sClockSourceConfig) != HAL_OK)
  {
    Error_Handler();
  }
  if (HAL_TIM_PWM_Init(&htim1) != HAL_OK)
  {
    Error_Handler();
  }
  sSlaveConfig.SlaveMode = TIM_SLAVEMODE_RESET;
  sSlaveConfig.InputTrigger = TIM_TS_ITR1;
  if (HAL_TIM_SlaveConfigSynchro(&htim1, &sSlaveConfig) != HAL_OK)
  {
    Error_Handler();
  }
  sMasterConfig.MasterOutputTrigger = TIM_TRGO_RESET;
  sMasterConfig.MasterOutputTrigger2 = TIM_TRGO2_RESET;
  sMasterConfig.MasterSlaveMode = TIM_MASTERSLAVEMODE_DISABLE;
  if (HAL_TIMEx_MasterConfigSynchronization(&htim1, &sMasterConfig) != HAL_OK)
  {
    Error_Handler();
  }
  sConfigOC.OCMode = TIM_OCMODE_PWM1;
  sConfigOC.Pulse = 0;
  sConfigOC.OCPolarity = TIM_OCPOLARITY_HIGH;
  sConfigOC.OCNPolarity = TIM_OCNPOLARITY_HIGH;
  sConfigOC.OCFastMode = TIM_OCFAST_DISABLE;
  sConfigOC.OCIdleState = TIM_OCIDLESTATE_RESET;
  sConfigOC.OCNIdleState = TIM_OCNIDLESTATE_RESET;
  if (HAL_TIM_PWM_ConfigChannel(&htim1, &sConfigOC, TIM_CHANNEL_1) != HAL_OK)
  {
    Error_Handler();
  }
  if (HAL_TIM_PWM_ConfigChannel(&htim1, &sConfigOC, TIM_CHANNEL_2) != HAL_OK)
  {
    Error_Handler();
  }
  if (HAL_TIM_PWM_ConfigChannel(&htim1, &sConfigOC, TIM_CHANNEL_3) != HAL_OK)
  {
    Error_Handler();
  }
  if (HAL_TIM_PWM_ConfigChannel(&htim1, &sConfigOC, TIM_CHANNEL_4) != HAL_OK)
  {
    Error_Handler();
  }
  sBreakDeadTimeConfig.OffStateRunMode = TIM_OSSR_DISABLE;
  sBreakDeadTimeConfig.OffStateIDLEMode = TIM_OSSI_DISABLE;
  sBreakDeadTimeConfig.LockLevel = TIM_LOCKLEVEL_OFF;
  sBreakDeadTimeConfig.DeadTime = 0;
  sBreakDeadTimeConfig.BreakState = TIM_BREAK_DISABLE;
  sBreakDeadTimeConfig.BreakPolarity = TIM_BREAKPOLARITY_HIGH;
  sBreakDeadTimeConfig.BreakFilter = 0;
  sBreakDeadTimeConfig.Break2State = TIM_BREAK2_DISABLE;
  sBreakDeadTimeConfig.Break2Polarity = TIM_BREAK2POLARITY_HIGH;
  sBreakDeadTimeConfig.Break2Filter = 0;
  sBreakDeadTimeConfig.AutomaticOutput = TIM_AUTOMATICOUTPUT_DISABLE;
  if (HAL_TIMEx_ConfigBreakDeadTime(&htim1, &sBreakDeadTimeConfig) != HAL_OK)
  {
    Error_Handler();
  }
  HAL_TIM_MspPostInit(&htim1);

}

static void MX_TIM2_Init(void)
{

  TIM_ClockConfigTypeDef sClockSourceConfig = {0};
  TIM_MasterConfigTypeDef sMasterConfig = {0};
  TIM_IC_InitTypeDef sConfigIC = {0};

  htim2.Instance = TIM2;
  htim2.Init.Prescaler = 0;
  htim2.Init.CounterMode = TIM_COUNTERMODE_UP;
  htim2.Init.Period = 0xffffffff;
  htim2.Init.ClockDivision = TIM_CLOCKDIVISION_DIV1;
  htim2.Init.AutoReloadPreload = TIM_AUTORELOAD_PRELOAD_DISABLE;
  if (HAL_TIM_Base_Init(&htim2) != HAL_OK)
  {
    Error_Handler();
  }
  sClockSourceConfig.ClockSource = TIM_CLOCKSOURCE_INTERNAL;
  if (HAL_TIM_ConfigClockSource(&htim2, &sClockSourceConfig) != HAL_OK)
  {
    Error_Handler();
  }
  if (HAL_TIM_IC_Init(&htim2) != HAL_OK)
  {
    Error_Handler();
  }
  sMasterConfig.MasterOutputTrigger = TIM_TRGO_OC1;
  sMasterConfig.MasterSlaveMode = TIM_MASTERSLAVEMODE_ENABLE;
  if (HAL_TIMEx_MasterConfigSynchronization(&htim2, &sMasterConfig) != HAL_OK)
  {
    Error_Handler();
  }
  sConfigIC.ICPolarity = TIM_INPUTCHANNELPOLARITY_BOTHEDGE;
  sConfigIC.ICSelection = TIM_ICSELECTION_DIRECTTI;
  sConfigIC.ICPrescaler = TIM_ICPSC_DIV1;
  sConfigIC.ICFilter = 0;
  if (HAL_TIM_IC_ConfigChannel(&htim2, &sConfigIC, TIM_CHANNEL_1) != HAL_OK)
  {
    Error_Handler();
  }
  if (HAL_TIM_IC_ConfigChannel(&htim2, &sConfigIC, TIM_CHANNEL_2) != HAL_OK)
  {
    Error_Handler();
  }
  if (HAL_TIM_IC_ConfigChannel(&htim2, &sConfigIC, TIM_CHANNEL_3) != HAL_OK)
  {
    Error_Handler();
  }
  if (HAL_TIM_IC_ConfigChannel(&htim2, &sConfigIC, TIM_CHANNEL_4) != HAL_OK)
  {
    Error_Handler();
  }
  /* USER CODE BEGIN TIM2_Init 2 */

  TIM_HandleTypeDef *htim = &htim2;
  TIM_TypeDef *tim = htim->Instance;

  tim->CR1 &= ~(TIM_CR1_CEN);
  tim->CR2 &= ~(TIM_CR2_CCDS); /* dma request sent when CCx event occurs */
  tim->DIER |= (TIM_DIER_CC1DE | TIM_DIER_CC2DE | TIM_DIER_CC3DE | TIM_DIER_CC4DE);
  tim->CCER |= (TIM_CCER_CC1E | TIM_CCER_CC2E | TIM_CCER_CC3E | TIM_CCER_CC4E);
  tim->CCER &= ~(TIM_CCER_CC1P_Msk | TIM_CCER_CC1NP_Msk);
  tim->CCER &= ~(TIM_CCER_CC2P_Msk | TIM_CCER_CC2NP_Msk);
  tim->CCER &= ~(TIM_CCER_CC3P_Msk | TIM_CCER_CC3NP_Msk);
  tim->CCER &= ~(TIM_CCER_CC4P_Msk | TIM_CCER_CC4NP_Msk);

  /* as input channel CCxNP/CCxP == 1/1 channel is sensitive to both edges */
  tim->CCER |= (TIM_CCER_CC1NP);
  tim->CCER |= (TIM_CCER_CC2NP);
  tim->CCER |= (TIM_CCER_CC3NP);
  tim->CCER |= (TIM_CCER_CC4NP);
  tim->CCER |= (TIM_CCER_CC1P);
  tim->CCER |= (TIM_CCER_CC2P);
  tim->CCER |= (TIM_CCER_CC3P);
  tim->CCER |= (TIM_CCER_CC4P);

  tim->DCR = (13 << TIM_DCR_DBA_Pos) | ((DShotChannels - 1) << TIM_DCR_DBL_Pos); /* start at CCR1. load 4 channels */

  tim->CR1 |= (TIM_CR1_CEN);

  /* USER CODE END TIM2_Init 2 */

}

static void MX_TIM3_Init(void)
{

  TIM_ClockConfigTypeDef sClockSourceConfig = {0};
  TIM_SlaveConfigTypeDef sSlaveConfig = {0};
  TIM_MasterConfigTypeDef sMasterConfig = {0};
  TIM_OC_InitTypeDef sConfigOC = {0};

  htim3.Instance = TIM3;
  htim3.Init.Prescaler = 0;
  htim3.Init.CounterMode = TIM_COUNTERMODE_UP;
  htim3.Init.Period = 199;
  htim3.Init.ClockDivision = TIM_CLOCKDIVISION_DIV1;
  htim3.Init.AutoReloadPreload = TIM_AUTORELOAD_PRELOAD_ENABLE;
  if (HAL_TIM_Base_Init(&htim3) != HAL_OK)
  {
    Error_Handler();
  }
  sClockSourceConfig.ClockSource = TIM_CLOCKSOURCE_INTERNAL;
  if (HAL_TIM_ConfigClockSource(&htim3, &sClockSourceConfig) != HAL_OK)
  {
    Error_Handler();
  }
  if (HAL_TIM_PWM_Init(&htim3) != HAL_OK)
  {
    Error_Handler();
  }
  sSlaveConfig.SlaveMode = TIM_SLAVEMODE_RESET;
  sSlaveConfig.InputTrigger = TIM_TS_ITR1;
  if (HAL_TIM_SlaveConfigSynchro(&htim3, &sSlaveConfig) != HAL_OK)
  {
    Error_Handler();
  }
  sMasterConfig.MasterOutputTrigger = TIM_TRGO_RESET;
  sMasterConfig.MasterSlaveMode = TIM_MASTERSLAVEMODE_DISABLE;
  if (HAL_TIMEx_MasterConfigSynchronization(&htim3, &sMasterConfig) != HAL_OK)
  {
    Error_Handler();
  }
  sConfigOC.OCMode = TIM_OCMODE_PWM1;
  sConfigOC.Pulse = 0;
  sConfigOC.OCPolarity = TIM_OCPOLARITY_HIGH;
  sConfigOC.OCFastMode = TIM_OCFAST_DISABLE;
  if (HAL_TIM_PWM_ConfigChannel(&htim3, &sConfigOC, TIM_CHANNEL_1) != HAL_OK)
  {
    Error_Handler();
  }
  if (HAL_TIM_PWM_ConfigChannel(&htim3, &sConfigOC, TIM_CHANNEL_2) != HAL_OK)
  {
    Error_Handler();
  }
  if (HAL_TIM_PWM_ConfigChannel(&htim3, &sConfigOC, TIM_CHANNEL_3) != HAL_OK)
  {
    Error_Handler();
  }
  if (HAL_TIM_PWM_ConfigChannel(&htim3, &sConfigOC, TIM_CHANNEL_4) != HAL_OK)
  {
    Error_Handler();
  }
  /* USER CODE BEGIN TIM3_Init 2 */

  TIM_TypeDef *tim = TIM3;
  tim->CR1 &= ~(TIM_CR1_CEN);
  tim->ARR = DShotPeriod;
  tim->CCR1 = 0;
  tim->CCR2 = 0;
  tim->CCR3 = 0;
  tim->CCR4 = 0;
  tim->CCER |= (TIM_CCER_CC1E | TIM_CCER_CC2E | TIM_CCER_CC3E | TIM_CCER_CC4E);
  // tim->DIER |= (TIM_DIER_UIE);

  tim->DCR = (13 << TIM_DCR_DBA_Pos) | ((DShotChannels - 1) << TIM_DCR_DBL_Pos); /* start at CCR1. load 4 channels */

  DMA_HandleTypeDef *hdma = htim3.hdma[0];
  DMA_Stream_TypeDef *dma_stream = hdma->Instance;
  dma_stream->PAR = &tim->DMAR;
  dma_stream->M0AR = dshot_ccr_buffer;
  dma_stream->NDTR = DShotChannels * DShotPacketLength;

  tim->CR1 &= ~(TIM_CR1_ARPE);

  tim->CR2 |= (TIM_CR2_CCDS); /* send dma request when update occurs */

  tim->CR1 |= (TIM_CR1_CEN);

  tim->DIER |= (TIM_DIER_UDE); /* enable dma request for updates */

  /* USER CODE END TIM3_Init 2 */
  HAL_TIM_MspPostInit(&htim3);

}

static void MX_TIM4_Init(void)
{

  TIM_ClockConfigTypeDef sClockSourceConfig = {0};
  TIM_MasterConfigTypeDef sMasterConfig = {0};
  TIM_OC_InitTypeDef sConfigOC = {0};

  htim4.Instance = TIM4;
  htim4.Init.Prescaler = 0;
  htim4.Init.CounterMode = TIM_COUNTERMODE_UP;
  htim4.Init.Period = 0;
  htim4.Init.ClockDivision = TIM_CLOCKDIVISION_DIV1;
  htim4.Init.AutoReloadPreload = TIM_AUTORELOAD_PRELOAD_DISABLE;
  if (HAL_TIM_Base_Init(&htim4) != HAL_OK)
  {
    Error_Handler();
  }
  sClockSourceConfig.ClockSource = TIM_CLOCKSOURCE_INTERNAL;
  if (HAL_TIM_ConfigClockSource(&htim4, &sClockSourceConfig) != HAL_OK)
  {
    Error_Handler();
  }
  if (HAL_TIM_PWM_Init(&htim4) != HAL_OK)
  {
    Error_Handler();
  }
  sMasterConfig.MasterOutputTrigger = TIM_TRGO_RESET;
  sMasterConfig.MasterSlaveMode = TIM_MASTERSLAVEMODE_DISABLE;
  if (HAL_TIMEx_MasterConfigSynchronization(&htim4, &sMasterConfig) != HAL_OK)
  {
    Error_Handler();
  }
  sConfigOC.OCMode = TIM_OCMODE_PWM1;
  sConfigOC.Pulse = 0;
  sConfigOC.OCPolarity = TIM_OCPOLARITY_HIGH;
  sConfigOC.OCFastMode = TIM_OCFAST_DISABLE;
  if (HAL_TIM_PWM_ConfigChannel(&htim4, &sConfigOC, TIM_CHANNEL_1) != HAL_OK)
  {
    Error_Handler();
  }
  if (HAL_TIM_PWM_ConfigChannel(&htim4, &sConfigOC, TIM_CHANNEL_2) != HAL_OK)
  {
    Error_Handler();
  }
  if (HAL_TIM_PWM_ConfigChannel(&htim4, &sConfigOC, TIM_CHANNEL_3) != HAL_OK)
  {
    Error_Handler();
  }
  if (HAL_TIM_PWM_ConfigChannel(&htim4, &sConfigOC, TIM_CHANNEL_4) != HAL_OK)
  {
    Error_Handler();
  }
  HAL_TIM_MspPostInit(&htim4);

}

static void MX_TIM5_Init(void)
{

  TIM_ClockConfigTypeDef sClockSourceConfig = {0};
  TIM_MasterConfigTypeDef sMasterConfig = {0};
  TIM_IC_InitTypeDef sConfigIC = {0};

  htim5.Instance = TIM5;
  htim5.Init.Prescaler = 0;
  htim5.Init.CounterMode = TIM_COUNTERMODE_UP;
  htim5.Init.Period = 0xffffffff;
  htim5.Init.ClockDivision = TIM_CLOCKDIVISION_DIV1;
  htim5.Init.AutoReloadPreload = TIM_AUTORELOAD_PRELOAD_DISABLE;
  if (HAL_TIM_Base_Init(&htim5) != HAL_OK)
  {
    Error_Handler();
  }
  sClockSourceConfig.ClockSource = TIM_CLOCKSOURCE_INTERNAL;
  if (HAL_TIM_ConfigClockSource(&htim5, &sClockSourceConfig) != HAL_OK)
  {
    Error_Handler();
  }
  if (HAL_TIM_IC_Init(&htim5) != HAL_OK)
  {
    Error_Handler();
  }
  sMasterConfig.MasterOutputTrigger = TIM_TRGO_RESET;
  sMasterConfig.MasterSlaveMode = TIM_MASTERSLAVEMODE_DISABLE;
  if (HAL_TIMEx_MasterConfigSynchronization(&htim5, &sMasterConfig) != HAL_OK)
  {
    Error_Handler();
  }
  sConfigIC.ICPolarity = TIM_INPUTCHANNELPOLARITY_BOTHEDGE;
  sConfigIC.ICSelection = TIM_ICSELECTION_DIRECTTI;
  sConfigIC.ICPrescaler = TIM_ICPSC_DIV1;
  sConfigIC.ICFilter = 0;
  if (HAL_TIM_IC_ConfigChannel(&htim5, &sConfigIC, TIM_CHANNEL_1) != HAL_OK)
  {
    Error_Handler();
  }
  if (HAL_TIM_IC_ConfigChannel(&htim5, &sConfigIC, TIM_CHANNEL_2) != HAL_OK)
  {
    Error_Handler();
  }
  if (HAL_TIM_IC_ConfigChannel(&htim5, &sConfigIC, TIM_CHANNEL_3) != HAL_OK)
  {
    Error_Handler();
  }
  if (HAL_TIM_IC_ConfigChannel(&htim5, &sConfigIC, TIM_CHANNEL_4) != HAL_OK)
  {
    Error_Handler();
  }
  /* USER CODE BEGIN TIM5_Init 2 */

  TIM_HandleTypeDef *htim = &htim5;
  TIM_TypeDef *tim = htim->Instance;

  tim->CR1 &= ~(TIM_CR1_CEN);
  tim->CR2 &= ~(TIM_CR2_CCDS); /* dma request sent when CCx event occurs */
  tim->DIER |= (TIM_DIER_CC1DE | TIM_DIER_CC2DE | TIM_DIER_CC3DE | TIM_DIER_CC4DE);
  tim->CCER |= (TIM_CCER_CC1E | TIM_CCER_CC2E | TIM_CCER_CC3E | TIM_CCER_CC4E);
  tim->CCER &= ~(TIM_CCER_CC1P_Msk | TIM_CCER_CC1NP_Msk);
  tim->CCER &= ~(TIM_CCER_CC2P_Msk | TIM_CCER_CC2NP_Msk);
  tim->CCER &= ~(TIM_CCER_CC3P_Msk | TIM_CCER_CC3NP_Msk);
  tim->CCER &= ~(TIM_CCER_CC4P_Msk | TIM_CCER_CC4NP_Msk);

  /* as input channel CCxNP/CCxP == 1/1 channel is sensitive to both edges */
  tim->CCER |= (TIM_CCER_CC1NP);
  tim->CCER |= (TIM_CCER_CC2NP);
  tim->CCER |= (TIM_CCER_CC3NP);
  tim->CCER |= (TIM_CCER_CC4NP);
  tim->CCER |= (TIM_CCER_CC1P);
  tim->CCER |= (TIM_CCER_CC2P);
  tim->CCER |= (TIM_CCER_CC3P);
  tim->CCER |= (TIM_CCER_CC4P);

  tim->DCR = (13 << TIM_DCR_DBA_Pos) | ((DShotChannels - 1) << TIM_DCR_DBL_Pos); /* start at CCR1. load 4 channels */

  tim->CR1 |= (TIM_CR1_CEN);

  /* USER CODE END TIM5_Init 2 */

}

static void MX_TIM8_Init(void)
{

  TIM_ClockConfigTypeDef sClockSourceConfig = {0};
  TIM_MasterConfigTypeDef sMasterConfig = {0};
  TIM_IC_InitTypeDef sConfigIC = {0};
  TIM_OC_InitTypeDef sConfigOC = {0};
  TIM_BreakDeadTimeConfigTypeDef sBreakDeadTimeConfig = {0};

  htim8.Instance = TIM8;
  htim8.Init.Prescaler = 0;
  htim8.Init.CounterMode = TIM_COUNTERMODE_UP;
  htim8.Init.Period = 0;
  htim8.Init.ClockDivision = TIM_CLOCKDIVISION_DIV1;
  htim8.Init.RepetitionCounter = 0;
  htim8.Init.AutoReloadPreload = TIM_AUTORELOAD_PRELOAD_DISABLE;
  if (HAL_TIM_Base_Init(&htim8) != HAL_OK)
  {
    Error_Handler();
  }
  sClockSourceConfig.ClockSource = TIM_CLOCKSOURCE_INTERNAL;
  if (HAL_TIM_ConfigClockSource(&htim8, &sClockSourceConfig) != HAL_OK)
  {
    Error_Handler();
  }
  if (HAL_TIM_IC_Init(&htim8) != HAL_OK)
  {
    Error_Handler();
  }
  if (HAL_TIM_PWM_Init(&htim8) != HAL_OK)
  {
    Error_Handler();
  }
  if (HAL_TIM_OC_Init(&htim8) != HAL_OK)
  {
    Error_Handler();
  }
  sMasterConfig.MasterOutputTrigger = TIM_TRGO_RESET;
  sMasterConfig.MasterOutputTrigger2 = TIM_TRGO2_RESET;
  sMasterConfig.MasterSlaveMode = TIM_MASTERSLAVEMODE_DISABLE;
  if (HAL_TIMEx_MasterConfigSynchronization(&htim8, &sMasterConfig) != HAL_OK)
  {
    Error_Handler();
  }
  sConfigIC.ICPolarity = TIM_INPUTCHANNELPOLARITY_RISING;
  sConfigIC.ICSelection = TIM_ICSELECTION_DIRECTTI;
  sConfigIC.ICPrescaler = TIM_ICPSC_DIV1;
  sConfigIC.ICFilter = 0;
  if (HAL_TIM_IC_ConfigChannel(&htim8, &sConfigIC, TIM_CHANNEL_1) != HAL_OK)
  {
    Error_Handler();
  }
  if (HAL_TIM_IC_ConfigChannel(&htim8, &sConfigIC, TIM_CHANNEL_2) != HAL_OK)
  {
    Error_Handler();
  }
  sConfigOC.OCMode = TIM_OCMODE_PWM1;
  sConfigOC.Pulse = 0;
  sConfigOC.OCPolarity = TIM_OCPOLARITY_HIGH;
  sConfigOC.OCNPolarity = TIM_OCNPOLARITY_HIGH;
  sConfigOC.OCFastMode = TIM_OCFAST_DISABLE;
  sConfigOC.OCIdleState = TIM_OCIDLESTATE_RESET;
  sConfigOC.OCNIdleState = TIM_OCNIDLESTATE_RESET;
  if (HAL_TIM_PWM_ConfigChannel(&htim8, &sConfigOC, TIM_CHANNEL_3) != HAL_OK)
  {
    Error_Handler();
  }
  if (HAL_TIM_PWM_ConfigChannel(&htim8, &sConfigOC, TIM_CHANNEL_4) != HAL_OK)
  {
    Error_Handler();
  }
  if (HAL_TIM_PWM_ConfigChannel(&htim8, &sConfigOC, TIM_CHANNEL_5) != HAL_OK)
  {
    Error_Handler();
  }
  sConfigOC.OCMode = TIM_OCMODE_TIMING;
  if (HAL_TIM_OC_ConfigChannel(&htim8, &sConfigOC, TIM_CHANNEL_6) != HAL_OK)
  {
    Error_Handler();
  }
  sBreakDeadTimeConfig.OffStateRunMode = TIM_OSSR_DISABLE;
  sBreakDeadTimeConfig.OffStateIDLEMode = TIM_OSSI_DISABLE;
  sBreakDeadTimeConfig.LockLevel = TIM_LOCKLEVEL_OFF;
  sBreakDeadTimeConfig.DeadTime = 0;
  sBreakDeadTimeConfig.BreakState = TIM_BREAK_DISABLE;
  sBreakDeadTimeConfig.BreakPolarity = TIM_BREAKPOLARITY_HIGH;
  sBreakDeadTimeConfig.BreakFilter = 0;
  sBreakDeadTimeConfig.Break2State = TIM_BREAK2_DISABLE;
  sBreakDeadTimeConfig.Break2Polarity = TIM_BREAK2POLARITY_HIGH;
  sBreakDeadTimeConfig.Break2Filter = 0;
  sBreakDeadTimeConfig.AutomaticOutput = TIM_AUTOMATICOUTPUT_DISABLE;
  if (HAL_TIMEx_ConfigBreakDeadTime(&htim8, &sBreakDeadTimeConfig) != HAL_OK)
  {
    Error_Handler();
  }
  HAL_TIM_MspPostInit(&htim8);

}

static void MX_USART1_UART_Init(void)
{

  huart1.Instance = USART1;
  huart1.Init.BaudRate = 115200;
  huart1.Init.WordLength = UART_WORDLENGTH_8B;
  huart1.Init.StopBits = UART_STOPBITS_1;
  huart1.Init.Parity = UART_PARITY_NONE;
  huart1.Init.Mode = UART_MODE_TX_RX;
  huart1.Init.HwFlowCtl = UART_HWCONTROL_NONE;
  huart1.Init.OverSampling = UART_OVERSAMPLING_16;
  huart1.Init.OneBitSampling = UART_ONE_BIT_SAMPLE_DISABLE;
  huart1.Init.ClockPrescaler = UART_PRESCALER_DIV1;
  huart1.AdvancedInit.AdvFeatureInit = UART_ADVFEATURE_NO_INIT;
  if (HAL_UART_Init(&huart1) != HAL_OK)
  {
    Error_Handler();
  }
  if (HAL_UARTEx_SetTxFifoThreshold(&huart1, UART_TXFIFO_THRESHOLD_1_8) != HAL_OK)
  {
    Error_Handler();
  }
  if (HAL_UARTEx_SetRxFifoThreshold(&huart1, UART_RXFIFO_THRESHOLD_1_8) != HAL_OK)
  {
    Error_Handler();
  }
  if (HAL_UARTEx_DisableFifoMode(&huart1) != HAL_OK)
  {
    Error_Handler();
  }

}

static void MX_USART2_UART_Init(void)
{

  huart2.Instance = USART2;
  huart2.Init.BaudRate = 115200;
  huart2.Init.WordLength = UART_WORDLENGTH_8B;
  huart2.Init.StopBits = UART_STOPBITS_1;
  huart2.Init.Parity = UART_PARITY_NONE;
  huart2.Init.Mode = UART_MODE_TX_RX;
  huart2.Init.HwFlowCtl = UART_HWCONTROL_NONE;
  huart2.Init.OverSampling = UART_OVERSAMPLING_16;
  huart2.Init.OneBitSampling = UART_ONE_BIT_SAMPLE_DISABLE;
  huart2.Init.ClockPrescaler = UART_PRESCALER_DIV1;
  huart2.AdvancedInit.AdvFeatureInit = UART_ADVFEATURE_NO_INIT;
  if (HAL_UART_Init(&huart2) != HAL_OK)
  {
    Error_Handler();
  }
  if (HAL_UARTEx_SetTxFifoThreshold(&huart2, UART_TXFIFO_THRESHOLD_1_8) != HAL_OK)
  {
    Error_Handler();
  }
  if (HAL_UARTEx_SetRxFifoThreshold(&huart2, UART_RXFIFO_THRESHOLD_1_8) != HAL_OK)
  {
    Error_Handler();
  }
  if (HAL_UARTEx_DisableFifoMode(&huart2) != HAL_OK)
  {
    Error_Handler();
  }

}

static void MX_USART3_UART_Init(void)
{

  huart3.Instance = USART3;
  huart3.Init.BaudRate = 115200;
  huart3.Init.WordLength = UART_WORDLENGTH_8B;
  huart3.Init.StopBits = UART_STOPBITS_1;
  huart3.Init.Parity = UART_PARITY_NONE;
  huart3.Init.Mode = UART_MODE_TX_RX;
  huart3.Init.HwFlowCtl = UART_HWCONTROL_NONE;
  huart3.Init.OverSampling = UART_OVERSAMPLING_16;
  huart3.Init.OneBitSampling = UART_ONE_BIT_SAMPLE_DISABLE;
  huart3.Init.ClockPrescaler = UART_PRESCALER_DIV1;
  huart3.AdvancedInit.AdvFeatureInit = UART_ADVFEATURE_NO_INIT;
  if (HAL_UART_Init(&huart3) != HAL_OK)
  {
    Error_Handler();
  }
  if (HAL_UARTEx_SetTxFifoThreshold(&huart3, UART_TXFIFO_THRESHOLD_1_8) != HAL_OK)
  {
    Error_Handler();
  }
  if (HAL_UARTEx_SetRxFifoThreshold(&huart3, UART_RXFIFO_THRESHOLD_1_8) != HAL_OK)
  {
    Error_Handler();
  }
  if (HAL_UARTEx_DisableFifoMode(&huart3) != HAL_OK)
  {
    Error_Handler();
  }

}

static void MX_DMA_Init(void)
{

  /* DMA controller clock enable */
  __HAL_RCC_DMA1_CLK_ENABLE();
  __HAL_RCC_DMA2_CLK_ENABLE();

  /* DMA interrupt init */
  /* DMA1_Stream0_IRQn interrupt configuration */
  HAL_NVIC_SetPriority(DMA1_Stream0_IRQn, 0, 0);
  HAL_NVIC_EnableIRQ(DMA1_Stream0_IRQn);
  /* DMA1_Stream1_IRQn interrupt configuration */
  HAL_NVIC_SetPriority(DMA1_Stream1_IRQn, 0, 0);
  HAL_NVIC_EnableIRQ(DMA1_Stream1_IRQn);
  /* DMA1_Stream2_IRQn interrupt configuration */
  HAL_NVIC_SetPriority(DMA1_Stream2_IRQn, 0, 0);
  HAL_NVIC_EnableIRQ(DMA1_Stream2_IRQn);
  /* DMA1_Stream3_IRQn interrupt configuration */
  HAL_NVIC_SetPriority(DMA1_Stream3_IRQn, 0, 0);
  HAL_NVIC_EnableIRQ(DMA1_Stream3_IRQn);
  /* DMA1_Stream4_IRQn interrupt configuration */
  HAL_NVIC_SetPriority(DMA1_Stream4_IRQn, 0, 0);
  HAL_NVIC_EnableIRQ(DMA1_Stream4_IRQn);
  /* DMA1_Stream5_IRQn interrupt configuration */
  HAL_NVIC_SetPriority(DMA1_Stream5_IRQn, 0, 0);
  HAL_NVIC_EnableIRQ(DMA1_Stream5_IRQn);
  /* DMA1_Stream6_IRQn interrupt configuration */
  HAL_NVIC_SetPriority(DMA1_Stream6_IRQn, 0, 0);
  HAL_NVIC_EnableIRQ(DMA1_Stream6_IRQn);
  /* DMA1_Stream7_IRQn interrupt configuration */
  HAL_NVIC_SetPriority(DMA1_Stream7_IRQn, 0, 0);
  HAL_NVIC_EnableIRQ(DMA1_Stream7_IRQn);
  /* DMA2_Stream0_IRQn interrupt configuration */
  HAL_NVIC_SetPriority(DMA2_Stream0_IRQn, 0, 0);
  HAL_NVIC_EnableIRQ(DMA2_Stream0_IRQn);

}

static void MX_GPIO_Init(void)
{
  GPIO_InitTypeDef GPIO_InitStruct = {0};

  /* GPIO Ports Clock Enable */
  __HAL_RCC_GPIOF_CLK_ENABLE();
  __HAL_RCC_GPIOH_CLK_ENABLE();
  __HAL_RCC_GPIOC_CLK_ENABLE();
  __HAL_RCC_GPIOA_CLK_ENABLE();
  __HAL_RCC_GPIOB_CLK_ENABLE();
  __HAL_RCC_GPIOG_CLK_ENABLE();
  __HAL_RCC_GPIOE_CLK_ENABLE();
  __HAL_RCC_GPIOD_CLK_ENABLE();

  /*Configure GPIO pin Output Level */
  HAL_GPIO_WritePin(GPIOF, GPIO8_Pin|GPIO9_Pin|GPIO10_Pin|LED1_Pin
                          |LED2_Pin|LED3_Pin|LED4_Pin|LED5_Pin, GPIO_PIN_RESET);

  /*Configure GPIO pin Output Level */
  HAL_GPIO_WritePin(GPIOG, LED6_Pin|LED7_Pin|CONTROL1_Pin|CONTROL2_Pin
                          |CONTROL3_Pin|CONTROL4_Pin|CONTROL5_Pin|CONTROL6_Pin
                          |CONTROL7_Pin, GPIO_PIN_RESET);

  /*Configure GPIO pin Output Level */
  HAL_GPIO_WritePin(CONTROL8_GPIO_Port, CONTROL8_Pin, GPIO_PIN_RESET);

  /*Configure GPIO pins : GPIO0_Pin GPIO1_Pin GPIO2_Pin GPIO3_Pin
                           GPIO4_Pin GPIO5_Pin GPIO6_Pin GPIO7_Pin */
  GPIO_InitStruct.Pin = GPIO0_Pin|GPIO1_Pin|GPIO2_Pin|GPIO3_Pin
                          |GPIO4_Pin|GPIO5_Pin|GPIO6_Pin|GPIO7_Pin;
  GPIO_InitStruct.Mode = GPIO_MODE_INPUT;
  GPIO_InitStruct.Pull = GPIO_NOPULL;
  HAL_GPIO_Init(GPIOF, &GPIO_InitStruct);

  /*Configure GPIO pins : GPIO8_Pin GPIO9_Pin GPIO10_Pin LED1_Pin
                           LED2_Pin LED3_Pin LED4_Pin LED5_Pin */
  GPIO_InitStruct.Pin = GPIO8_Pin|GPIO9_Pin|GPIO10_Pin|LED1_Pin
                          |LED2_Pin|LED3_Pin|LED4_Pin|LED5_Pin;
  GPIO_InitStruct.Mode = GPIO_MODE_OUTPUT_PP;
  GPIO_InitStruct.Pull = GPIO_NOPULL;
  GPIO_InitStruct.Speed = GPIO_SPEED_FREQ_LOW;
  HAL_GPIO_Init(GPIOF, &GPIO_InitStruct);

  /*Configure GPIO pins : LED6_Pin LED7_Pin CONTROL1_Pin CONTROL2_Pin
                           CONTROL3_Pin CONTROL4_Pin CONTROL5_Pin CONTROL6_Pin
                           CONTROL7_Pin */
  GPIO_InitStruct.Pin = LED6_Pin|LED7_Pin|CONTROL1_Pin|CONTROL2_Pin
                          |CONTROL3_Pin|CONTROL4_Pin|CONTROL5_Pin|CONTROL6_Pin
                          |CONTROL7_Pin;
  GPIO_InitStruct.Mode = GPIO_MODE_OUTPUT_PP;
  GPIO_InitStruct.Pull = GPIO_NOPULL;
  GPIO_InitStruct.Speed = GPIO_SPEED_FREQ_LOW;
  HAL_GPIO_Init(GPIOG, &GPIO_InitStruct);

  /*Configure GPIO pin : CONTROL8_Pin */
  GPIO_InitStruct.Pin = CONTROL8_Pin;
  GPIO_InitStruct.Mode = GPIO_MODE_OUTPUT_PP;
  GPIO_InitStruct.Pull = GPIO_NOPULL;
  GPIO_InitStruct.Speed = GPIO_SPEED_FREQ_LOW;
  HAL_GPIO_Init(CONTROL8_GPIO_Port, &GPIO_InitStruct);

}

void Error_Handler(void)
{
}

/************************ (C) COPYRIGHT STMicroelectronics *****END OF FILE****/
